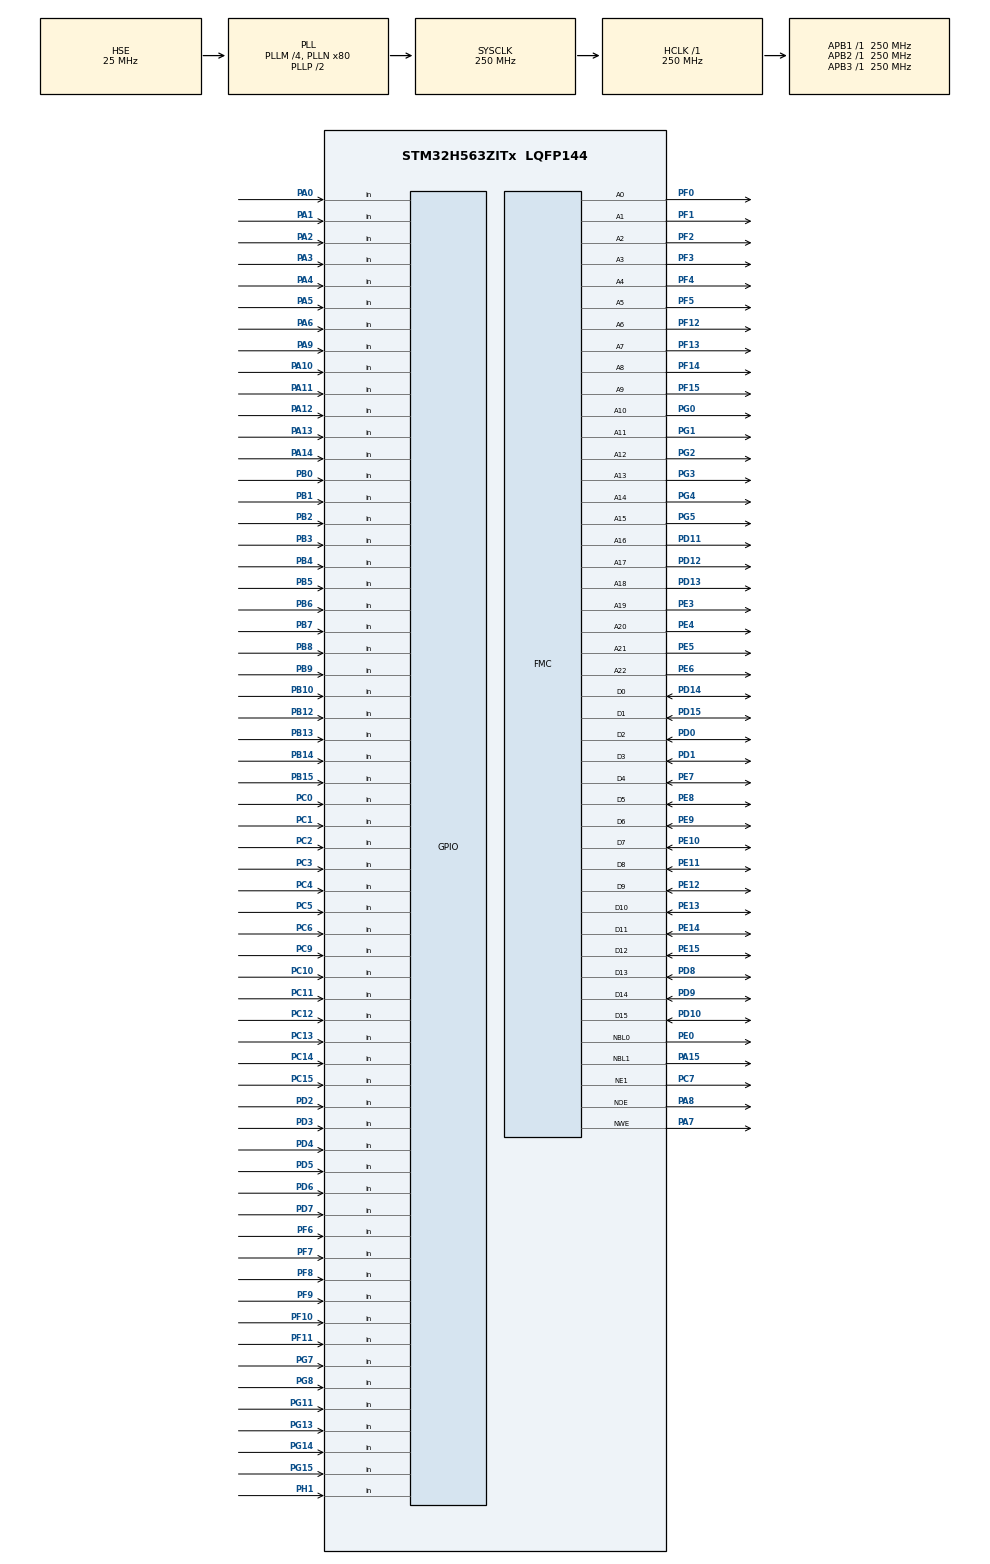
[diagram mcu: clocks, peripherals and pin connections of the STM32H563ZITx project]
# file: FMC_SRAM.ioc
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BOOTPATH.BootPathName=LEGACY
BOOTPATH.UserSelectedBootPath=LEGACY
CORTEX_M33_NS.userName=CORTEX_M33
FMC.AddressSetupTime1=5
FMC.BusTurnAroundDuration1=0
FMC.DataHoldTime1=1
FMC.DataSetupTime1=5
FMC.WriteOperation1=FMC_WRITE_OPERATION_ENABLE
Mcu.Family=STM32H5
Mcu.Name=STM32H563ZITx
Mcu.Package=LQFP144
NVIC.PriorityGroup=NVIC_PRIORITYGROUP_4
PA0.Signal=GPIO_Input
PA1.Signal=GPIO_Input
PA10.Signal=GPIO_Input
PA11.Signal=GPIO_Input
PA12.Signal=GPIO_Input
PA13(JTMS/SWDIO).Signal=GPIO_Input
PA14(JTCK/SWCLK).Signal=GPIO_Input
PA15(JTDI).Signal=FMC_NBL1
PA2.Signal=GPIO_Input
PA3.Signal=GPIO_Input
PA4.Signal=GPIO_Input
PA5.Signal=GPIO_Input
PA6.Signal=GPIO_Input
PA7.Signal=FMC_NWE
PA8.Signal=FMC_NOE
PA9.Signal=GPIO_Input
PB0.Signal=GPIO_Input
PB1.Signal=GPIO_Input
PB10.Signal=GPIO_Input
PB12.Signal=GPIO_Input
PB13.Signal=GPIO_Input
PB14.Signal=GPIO_Input
PB15.Signal=GPIO_Input
PB2.Signal=GPIO_Input
PB3(JTDO/TRACESWO).Signal=GPIO_Input
PB4(NJTRST).Signal=GPIO_Input
PB5.Signal=GPIO_Input
PB6.Signal=GPIO_Input
PB7.Signal=GPIO_Input
PB8.Signal=GPIO_Input
PB9.Signal=GPIO_Input
PC0.Signal=GPIO_Input
PC1.Signal=GPIO_Input
PC10.Signal=GPIO_Input
PC11.Signal=GPIO_Input
PC12.Signal=GPIO_Input
PC13.Signal=GPIO_Input
PC14-OSC32_IN(OSC32_IN).Signal=GPIO_Input
PC15-OSC32_OUT(OSC32_OUT).Signal=GPIO_Input
PC2.Signal=GPIO_Input
PC3.Signal=GPIO_Input
PC4.Signal=GPIO_Input
PC5.Signal=GPIO_Input
PC6.Signal=GPIO_Input
PC7.Mode=NorPsramChipSelect1_1
PC7.Signal=FMC_NE1
PC9.Signal=GPIO_Input
PD0.Signal=FMC_D2_DA2
PD1.Signal=FMC_D3_DA3
PD10.Signal=FMC_D15_DA15
PD11.Signal=FMC_A16_CLE
PD12.Signal=FMC_A17_ALE
PD13.Signal=FMC_A18
PD14.Signal=FMC_D0_DA0
PD15.Signal=FMC_D1_DA1
PD2.Signal=GPIO_Input
PD3.Signal=GPIO_Input
PD4.Signal=GPIO_Input
PD5.Signal=GPIO_Input
PD6.Signal=GPIO_Input
PD7.Signal=GPIO_Input
PD8.Signal=FMC_D13_DA13
PD9.Signal=FMC_D14_DA14
PE0.Signal=FMC_NBL0
PE10.Signal=FMC_D7_DA7
PE11.Signal=FMC_D8_DA8
PE12.Signal=FMC_D9_DA9
PE13.Signal=FMC_D10_DA10
PE14.Signal=FMC_D11_DA11
PE15.Signal=FMC_D12_DA12
PE3.Signal=FMC_A19
PE4.Signal=FMC_A20
PE5.Signal=FMC_A21
PE6.Signal=FMC_A22
PE7.Signal=FMC_D4_DA4
PE8.Signal=FMC_D5_DA5
PE9.Signal=FMC_D6_DA6
PF0.Signal=FMC_A0
PF1.Signal=FMC_A1
PF10.Signal=GPIO_Input
PF11.Signal=GPIO_Input
PF12.Signal=FMC_A6
PF13.Signal=FMC_A7
PF14.Signal=FMC_A8
PF15.Signal=FMC_A9
PF2.Signal=FMC_A2
PF3.Signal=FMC_A3
PF4.Signal=FMC_A4
PF5.Signal=FMC_A5
PF6.Signal=GPIO_Input
PF7.Signal=GPIO_Input
PF8.Signal=GPIO_Input
PF9.Signal=GPIO_Input
PG0.Signal=FMC_A10
PG1.Signal=FMC_A11
PG11.Signal=GPIO_Input
PG13.Signal=GPIO_Input
PG14.Signal=GPIO_Input
PG15.Signal=GPIO_Input
PG2.Signal=FMC_A12
PG3.Signal=FMC_A13
PG4.Signal=FMC_A14_BA0
PG5.Signal=FMC_A15_BA1
PG7.Signal=GPIO_Input
PG8.Signal=GPIO_Input
PH0-OSC_IN(PH0).Mode=HSE-DIG-External-Clock-Source
PH0-OSC_IN(PH0).Signal=RCC_OSC_IN
PH1-OSC_OUT(PH1).Signal=GPIO_Input
ProjectManager.HeapSize=0x200
ProjectManager.StackSize=0x400
ProjectManager.TargetToolchain=EWARM V8
RCC.ADCFreq_Value=250000000
RCC.AHBFreq_Value=250000000
RCC.APB1Freq_Value=250000000
RCC.APB1TimFreq_Value=250000000
RCC.APB2Freq_Value=250000000
RCC.APB2TimFreq_Value=250000000
RCC.APB3Freq_Value=250000000
RCC.CSI_VALUE=4000000
RCC.CortexFreq_Value=250000000
RCC.EPOD_VALUE=25000000
RCC.HCLKFreq_Value=250000000
RCC.HSE_VALUE=25000000
RCC.HSI48_VALUE=48000000
RCC.HSI_VALUE=64000000
RCC.LSE_VALUE=32768
RCC.LSIRC_VALUE=32000
RCC.PLLM=4
RCC.PLLN=80
RCC.PLLSourceVirtual=RCC_PLL1_SOURCE_HSE
RCC.SYSCLKFreq_VALUE=250000000
RCC.SYSCLKSource=RCC_SYSCLKSOURCE_PLLCLK
RCC.USBFreq_Value=48000000
RCC.VCOOutputFreq_Value=500000000
SH.FMC_A0.0=FMC_A0,23b-a1
SH.FMC_A1.0=FMC_A1,23b-a1
SH.FMC_A10.0=FMC_A10,23b-a1
SH.FMC_A11.0=FMC_A11,23b-a1
SH.FMC_A12.0=FMC_A12,23b-a1
SH.FMC_A13.0=FMC_A13,23b-a1
SH.FMC_A14_BA0.0=FMC_A14,23b-a1
SH.FMC_A15_BA1.0=FMC_A15,23b-a1
SH.FMC_A16_CLE.0=FMC_A16,23b-a1
SH.FMC_A17_ALE.0=FMC_A17,23b-a1
SH.FMC_A18.0=FMC_A18,23b-a1
SH.FMC_A19.0=FMC_A19,23b-a1
SH.FMC_A2.0=FMC_A2,23b-a1
SH.FMC_A20.0=FMC_A20,23b-a1
SH.FMC_A21.0=FMC_A21,23b-a1
SH.FMC_A22.0=FMC_A22,23b-a1
SH.FMC_A3.0=FMC_A3,23b-a1
SH.FMC_A4.0=FMC_A4,23b-a1
SH.FMC_A5.0=FMC_A5,23b-a1
SH.FMC_A6.0=FMC_A6,23b-a1
SH.FMC_A7.0=FMC_A7,23b-a1
SH.FMC_A8.0=FMC_A8,23b-a1
SH.FMC_A9.0=FMC_A9,23b-a1
SH.FMC_D0_DA0.0=FMC_D0,16b-d1
SH.FMC_D10_DA10.0=FMC_D10,16b-d1
SH.FMC_D11_DA11.0=FMC_D11,16b-d1
SH.FMC_D12_DA12.0=FMC_D12,16b-d1
SH.FMC_D13_DA13.0=FMC_D13,16b-d1
SH.FMC_D14_DA14.0=FMC_D14,16b-d1
SH.FMC_D15_DA15.0=FMC_D15,16b-d1
SH.FMC_D1_DA1.0=FMC_D1,16b-d1
SH.FMC_D2_DA2.0=FMC_D2,16b-d1
SH.FMC_D3_DA3.0=FMC_D3,16b-d1
SH.FMC_D4_DA4.0=FMC_D4,16b-d1
SH.FMC_D5_DA5.0=FMC_D5,16b-d1
SH.FMC_D6_DA6.0=FMC_D6,16b-d1
SH.FMC_D7_DA7.0=FMC_D7,16b-d1
SH.FMC_D8_DA8.0=FMC_D8,16b-d1
SH.FMC_D9_DA9.0=FMC_D9,16b-d1
SH.FMC_NBL0.0=FMC_NBL0,2ByteEnable1
SH.FMC_NBL1.0=FMC_NBL1,2ByteEnable1
SH.FMC_NOE.0=FMC_NOE,Sram1
SH.FMC_NWE.0=FMC_NWE,Sram1
VP_BOOTPATH_VS_BOOTPATH.Mode=BP_Activate
VP_ICACHE_VS_ICACHE.Mode=DefaultMode
VP_MEMORYMAP_VS_MEMORYMAP.Mode=CurAppReg
VP_PWR_VS_DBSignals.Mode=DisableDeadBatterySignals
VP_PWR_VS_LPOM.Mode=PowerOptimisation
VP_PWR_VS_SECSignals.Mode=Security/Privilege
board=custom

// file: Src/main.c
/* USER CODE BEGIN Header */
/**
  ******************************************************************************
  * @file    FMC/FMC_SRAM/Src/main.c
  * @author  MCD Application Team
  * @brief   This sample code shows how to configure the FMC controller to access
  *          the SRAM memory.
  ******************************************************************************
   * @attention
  *
  * Copyright (c) 2023 STMicroelectronics.
  * All rights reserved.
  *
  * This software is licensed under terms that can be found in the LICENSE file
  * in the root directory of this software component.
  * If no LICENSE file comes with this software, it is provided AS-IS.
  *
  *
  *
  ******************************************************************************
  */
/* USER CODE END Header */
#include "main.h"

SRAM_HandleTypeDef hsram1;

/* USER CODE BEGIN PV */
FMC_NORSRAM_TimingTypeDef SRAM_Timing;

/* Read/Write Buffers */
uint16_t aTxBuffer[BUFFER_SIZE];
uint16_t aRxBuffer[BUFFER_SIZE];

/* Status variables */
__IO uint32_t uwWriteReadStatus = 0;

/* Counter index */
uint32_t uwIndex = 0;
/* USER CODE END PV */

void SystemClock_Config(void);
static void MX_GPIO_Init(void);
static void MX_FMC_Init(void);
static void MX_ICACHE_Init(void);
/* USER CODE BEGIN PFP */
/* Private function prototypes -----------------------------------------------*/
static void Fill_Buffer(uint16_t *pBuffer, uint32_t uwBufferLength, uint16_t uwOffset);
static TestStatus Buffercmp(uint16_t *pBuffer1, uint16_t *pBuffer2, uint16_t BufferLength);
/* USER CODE END PFP */

int main(void)
{

  /* USER CODE BEGIN 1 */
  /* STM32H5xx HAL library initialization:
       - Systick timer is configured by default as source of time base, but user
             can eventually implement his proper time base source (a general purpose
             timer for example or other time source), keeping in mind that Time base
             duration should be kept 1ms since PPP_TIMEOUT_VALUEs are defined and
             handled in milliseconds basis.
       - Set NVIC Group Priority to 4
       - Low Level Initialization
     */
  /* USER CODE END 1 */

  /* MCU Configuration--------------------------------------------------------*/

  /* Reset of all peripherals, Initializes the Flash interface and the Systick. */
  HAL_Init();

  /* Configure the system clock */
  SystemClock_Config();

  /* Initialize all configured peripherals */
  MX_GPIO_Init();
  MX_FMC_Init();
  MX_ICACHE_Init();
  /* USER CODE BEGIN 2 */
  /* Fill the buffer to write */
  Fill_Buffer(aTxBuffer, BUFFER_SIZE, 0xC20F);

  /* Write data to the SRAM memory */
  for(uwIndex = 0; uwIndex < BUFFER_SIZE; uwIndex++)
  {
    *(__IO uint16_t *)(SRAM_BANK_ADDR + WRITE_READ_ADDR + 2 * uwIndex) = aTxBuffer[uwIndex];
  }

  /* Read back data from the SRAM memory */
  for(uwIndex = 0; uwIndex < BUFFER_SIZE; uwIndex++)
  {
    aRxBuffer[uwIndex] = *(__IO uint16_t *)(SRAM_BANK_ADDR + WRITE_READ_ADDR + 2 * uwIndex);
  }

  /* Checking data integrity */
  uwWriteReadStatus = Buffercmp(aTxBuffer, aRxBuffer, BUFFER_SIZE);

  if(uwWriteReadStatus != PASSED)
  {
    /* KO */

Error_Handler();

  }
  else
  {
    /* OK */

  }
  /* USER CODE END 2 */

  /* Infinite loop */
  while (1)
  {

  }
}

void SystemClock_Config(void)
{
  RCC_OscInitTypeDef RCC_OscInitStruct = {0};
  RCC_ClkInitTypeDef RCC_ClkInitStruct = {0};

  /** Configure the main internal regulator output voltage
  */
  __HAL_PWR_VOLTAGESCALING_CONFIG(PWR_REGULATOR_VOLTAGE_SCALE0);

  while(!__HAL_PWR_GET_FLAG(PWR_FLAG_VOSRDY)) {}

  /** Initializes the RCC Oscillators according to the specified parameters
  * in the RCC_OscInitTypeDef structure.
  */
  RCC_OscInitStruct.OscillatorType = RCC_OSCILLATORTYPE_HSE;
  RCC_OscInitStruct.HSEState = RCC_HSE_BYPASS_DIGITAL;
  RCC_OscInitStruct.PLL.PLLState = RCC_PLL_ON;
  RCC_OscInitStruct.PLL.PLLSource = RCC_PLL1_SOURCE_HSE;
  RCC_OscInitStruct.PLL.PLLM = 4;
  RCC_OscInitStruct.PLL.PLLN = 80;
  RCC_OscInitStruct.PLL.PLLP = 2;
  RCC_OscInitStruct.PLL.PLLQ = 2;
  RCC_OscInitStruct.PLL.PLLR = 2;
  RCC_OscInitStruct.PLL.PLLRGE = RCC_PLL1_VCIRANGE_2;
  RCC_OscInitStruct.PLL.PLLVCOSEL = RCC_PLL1_VCORANGE_WIDE;
  RCC_OscInitStruct.PLL.PLLFRACN = 0;
  if (HAL_RCC_OscConfig(&RCC_OscInitStruct) != HAL_OK)
  {
    Error_Handler();
  }

  /** Initializes the CPU, AHB and APB buses clocks
  */
  RCC_ClkInitStruct.ClockType = RCC_CLOCKTYPE_HCLK|RCC_CLOCKTYPE_SYSCLK
                              |RCC_CLOCKTYPE_PCLK1|RCC_CLOCKTYPE_PCLK2
                              |RCC_CLOCKTYPE_PCLK3;
  RCC_ClkInitStruct.SYSCLKSource = RCC_SYSCLKSOURCE_PLLCLK;
  RCC_ClkInitStruct.AHBCLKDivider = RCC_SYSCLK_DIV1;
  RCC_ClkInitStruct.APB1CLKDivider = RCC_HCLK_DIV1;
  RCC_ClkInitStruct.APB2CLKDivider = RCC_HCLK_DIV1;
  RCC_ClkInitStruct.APB3CLKDivider = RCC_HCLK_DIV1;

  if (HAL_RCC_ClockConfig(&RCC_ClkInitStruct, FLASH_LATENCY_5) != HAL_OK)
  {
    Error_Handler();
  }

  /** Configure the programming delay
  */
  __HAL_FLASH_SET_PROGRAM_DELAY(FLASH_PROGRAMMING_DELAY_2);
}

static void MX_ICACHE_Init(void)
{

  /** Enable instruction cache (default 2-ways set associative cache)
  */
  if (HAL_ICACHE_Enable() != HAL_OK)
  {
    Error_Handler();
  }

}

/* FMC initialization function */
static void MX_FMC_Init(void)
{

  FMC_NORSRAM_TimingTypeDef Timing = {0};

  /** Perform the SRAM1 memory initialization sequence
  */
  hsram1.Instance = FMC_NORSRAM_DEVICE;
  hsram1.Extended = FMC_NORSRAM_EXTENDED_DEVICE;
  /* hsram1.Init */
  hsram1.Init.NSBank = FMC_NORSRAM_BANK1;
  hsram1.Init.DataAddressMux = FMC_DATA_ADDRESS_MUX_DISABLE;
  hsram1.Init.MemoryType = FMC_MEMORY_TYPE_SRAM;
  hsram1.Init.MemoryDataWidth = FMC_NORSRAM_MEM_BUS_WIDTH_16;
  hsram1.Init.BurstAccessMode = FMC_BURST_ACCESS_MODE_DISABLE;
  hsram1.Init.WaitSignalPolarity = FMC_WAIT_SIGNAL_POLARITY_LOW;
  hsram1.Init.WaitSignalActive = FMC_WAIT_TIMING_BEFORE_WS;
  hsram1.Init.WriteOperation = FMC_WRITE_OPERATION_ENABLE;
  hsram1.Init.WaitSignal = FMC_WAIT_SIGNAL_DISABLE;
  hsram1.Init.ExtendedMode = FMC_EXTENDED_MODE_DISABLE;
  hsram1.Init.AsynchronousWait = FMC_ASYNCHRONOUS_WAIT_DISABLE;
  hsram1.Init.WriteBurst = FMC_WRITE_BURST_DISABLE;
  hsram1.Init.ContinuousClock = FMC_CONTINUOUS_CLOCK_SYNC_ONLY;
  hsram1.Init.WriteFifo = FMC_WRITE_FIFO_ENABLE;
  hsram1.Init.NBLSetupTime = 0;
  hsram1.Init.PageSize = FMC_PAGE_SIZE_NONE;
  hsram1.Init.MaxChipSelectPulse = DISABLE;
  /* Timing */
  Timing.AddressSetupTime = 5;
  Timing.AddressHoldTime = 15;
  Timing.DataSetupTime = 5;
  Timing.DataHoldTime = 1;
  Timing.BusTurnAroundDuration = 0;
  Timing.CLKDivision = 16;
  Timing.DataLatency = 17;
  Timing.AccessMode = FMC_ACCESS_MODE_A;
  /* ExtTiming */

  if (HAL_SRAM_Init(&hsram1, &Timing, NULL) != HAL_OK)
  {
    Error_Handler( );
  }

}

static void MX_GPIO_Init(void)
{
  GPIO_InitTypeDef GPIO_InitStruct = {0};

  /* GPIO Ports Clock Enable */
  __HAL_RCC_GPIOE_CLK_ENABLE();
  __HAL_RCC_GPIOC_CLK_ENABLE();
  __HAL_RCC_GPIOF_CLK_ENABLE();
  __HAL_RCC_GPIOH_CLK_ENABLE();
  __HAL_RCC_GPIOA_CLK_ENABLE();
  __HAL_RCC_GPIOB_CLK_ENABLE();
  __HAL_RCC_GPIOG_CLK_ENABLE();
  __HAL_RCC_GPIOD_CLK_ENABLE();

  /*Configure GPIO pins : PC13 PC14 PC15 PC0
                           PC1 PC2 PC3 PC4
                           PC5 PC6 PC9 PC10
                           PC11 PC12 */
  GPIO_InitStruct.Pin = GPIO_PIN_13|GPIO_PIN_14|GPIO_PIN_15|GPIO_PIN_0
                          |GPIO_PIN_1|GPIO_PIN_2|GPIO_PIN_3|GPIO_PIN_4
                          |GPIO_PIN_5|GPIO_PIN_6|GPIO_PIN_9|GPIO_PIN_10
                          |GPIO_PIN_11|GPIO_PIN_12;
  GPIO_InitStruct.Mode = GPIO_MODE_INPUT;
  GPIO_InitStruct.Pull = GPIO_NOPULL;
  HAL_GPIO_Init(GPIOC, &GPIO_InitStruct);

  /*Configure GPIO pins : PF6 PF7 PF8 PF9
                           PF10 PF11 */
  GPIO_InitStruct.Pin = GPIO_PIN_6|GPIO_PIN_7|GPIO_PIN_8|GPIO_PIN_9
                          |GPIO_PIN_10|GPIO_PIN_11;
  GPIO_InitStruct.Mode = GPIO_MODE_INPUT;
  GPIO_InitStruct.Pull = GPIO_NOPULL;
  HAL_GPIO_Init(GPIOF, &GPIO_InitStruct);

  /*Configure GPIO pin : PH1 */
  GPIO_InitStruct.Pin = GPIO_PIN_1;
  GPIO_InitStruct.Mode = GPIO_MODE_INPUT;
  GPIO_InitStruct.Pull = GPIO_NOPULL;
  HAL_GPIO_Init(GPIOH, &GPIO_InitStruct);

  /*Configure GPIO pins : PA0 PA1 PA2 PA3
                           PA4 PA5 PA6 PA9
                           PA10 PA11 PA12 PA13
                           PA14 */
  GPIO_InitStruct.Pin = GPIO_PIN_0|GPIO_PIN_1|GPIO_PIN_2|GPIO_PIN_3
                          |GPIO_PIN_4|GPIO_PIN_5|GPIO_PIN_6|GPIO_PIN_9
                          |GPIO_PIN_10|GPIO_PIN_11|GPIO_PIN_12|GPIO_PIN_13
                          |GPIO_PIN_14;
  GPIO_InitStruct.Mode = GPIO_MODE_INPUT;
  GPIO_InitStruct.Pull = GPIO_NOPULL;
  HAL_GPIO_Init(GPIOA, &GPIO_InitStruct);

  /*Configure GPIO pins : PB0 PB1 PB2 PB10
                           PB12 PB13 PB14 PB15
                           PB3 PB4 PB5 PB6
                           PB7 PB8 PB9 */
  GPIO_InitStruct.Pin = GPIO_PIN_0|GPIO_PIN_1|GPIO_PIN_2|GPIO_PIN_10
                          |GPIO_PIN_12|GPIO_PIN_13|GPIO_PIN_14|GPIO_PIN_15
                          |GPIO_PIN_3|GPIO_PIN_4|GPIO_PIN_5|GPIO_PIN_6
                          |GPIO_PIN_7|GPIO_PIN_8|GPIO_PIN_9;
  GPIO_InitStruct.Mode = GPIO_MODE_INPUT;
  GPIO_InitStruct.Pull = GPIO_NOPULL;
  HAL_GPIO_Init(GPIOB, &GPIO_InitStruct);

  /*Configure GPIO pins : PG7 PG8 PG11 PG13
                           PG14 PG15 */
  GPIO_InitStruct.Pin = GPIO_PIN_7|GPIO_PIN_8|GPIO_PIN_11|GPIO_PIN_13
                          |GPIO_PIN_14|GPIO_PIN_15;
  GPIO_InitStruct.Mode = GPIO_MODE_INPUT;
  GPIO_InitStruct.Pull = GPIO_NOPULL;
  HAL_GPIO_Init(GPIOG, &GPIO_InitStruct);

  /*Configure GPIO pins : PD2 PD3 PD4 PD5
                           PD6 PD7 */
  GPIO_InitStruct.Pin = GPIO_PIN_2|GPIO_PIN_3|GPIO_PIN_4|GPIO_PIN_5
                          |GPIO_PIN_6|GPIO_PIN_7;
  GPIO_InitStruct.Mode = GPIO_MODE_INPUT;
  GPIO_InitStruct.Pull = GPIO_NOPULL;
  HAL_GPIO_Init(GPIOD, &GPIO_InitStruct);

}

/* USER CODE BEGIN 4 */
/**
  * @brief  Fills buffer with user predefined data.
  * @param  pBuffer: pointer on the buffer to fill
  * @param  uwBufferLength: size of the buffer to fill
  * @param  uwOffset: first value to fill on the buffer
  * @retval None
  */
static void Fill_Buffer(uint16_t *pBuffer, uint32_t uwBufferLength, uint16_t uwOffset)
{
  uint16_t tmpIndex = 0;

  /* Put in global buffer different values */
  for (tmpIndex = 0; tmpIndex < uwBufferLength; tmpIndex++)
  {
    pBuffer[tmpIndex] = tmpIndex + uwOffset;
  }
}

/**
  * @brief  Compares two buffers.
  * @param  pBuffer1, pBuffer2: buffers to be compared.
  * @param  BufferLength: buffer's length
  * @retval PASSED: pBuffer identical to pBuffer1
  *         FAILED: pBuffer differs from pBuffer1
  */
static TestStatus Buffercmp(uint16_t *pBuffer1, uint16_t *pBuffer2, uint16_t BufferLength)
{
  while (BufferLength--)
  {
    if (*pBuffer1 != *pBuffer2)
    {
      return FAILED;
    }

    pBuffer1++;
    pBuffer2++;
  }

  return PASSED;
}
/* USER CODE END 4 */

void Error_Handler(void)
{
  while(1)
  {
  }
}
